# MIMXRT1064 register map
Vendor: nxp.com; File version: 1.0
CPU: CM7 r0p1, little endian, MPU, FPU, VTOR, 4 interrupt priority bits
Registers are 32-bit, read-write, reset 0x0 unless marked. A register's access mark holds for its fields unless they carry their own. Offsets are from the block's base; [hi:lo] are bit positions; lines under a group give offsets from that group; {n}, {i} and the like mark numbered series; 'fields as' and 'values as' point back to an identical list.

## DMA0 — DMA
Base 0x400E8000
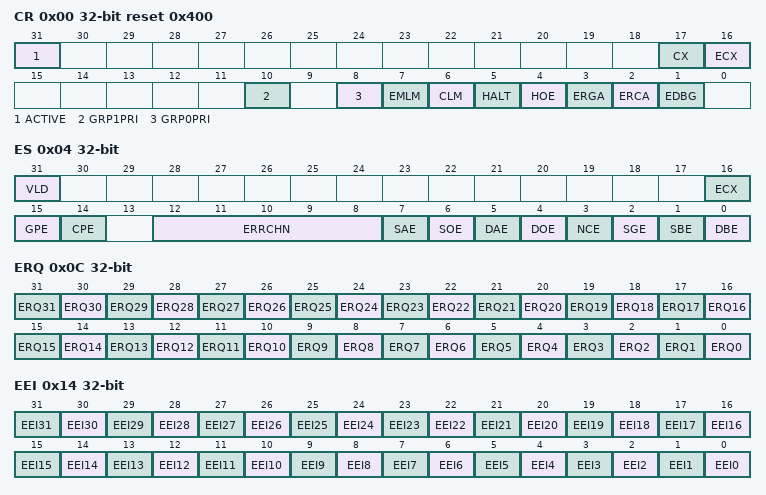
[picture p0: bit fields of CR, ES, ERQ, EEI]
0x00 CR reset 0x400 — Control Register
  [31] ACTIVE ro — DMA Active Status
    0=eDMA is idle; 1=eDMA is executing a channel
  [17] CX — Cancel Transfer
    0=Normal operation; 1=Cancel the remaining data transfer. Stop the executing channel and force the minor loop to finish. The cancel takes effect after the last write of the current read/write sequence. The CX bit clears itself after the cancel has been honored. This cancel retires the channel normally as if the minor loop was completed.
  [16] ECX — Error Cancel Transfer
    0=Normal operation; 1=Cancel the remaining data transfer in the same fashion as the CX bit. Stop the executing channel and force the minor loop to finish. The cancel takes effect after the last write of the current read/write sequence. The ECX bit clears itself after the cancel is honored. In addition to cancelling the transfer, ECX treats the cancel as an error condition, thus updating the Error Status register (DMAx_ES) and generating an optional error interrupt.
  [10] GRP1PRI — Channel Group 1 Priority
  [8] GRP0PRI — Channel Group 0 Priority
  [7] EMLM — Enable Minor Loop Mapping
    0=Disabled. TCDn.word2 is defined as a 32-bit NBYTES field.; 1=Enabled. TCDn.word2 is redefined to include individual enable fields, an offset field, and the NBYTES field. The individual enable fields allow the minor loop offset to be applied to the source address, the destination address, or both. The NBYTES field is reduced when either offset is enabled.
  [6] CLM — Continuous Link Mode
    0=A minor loop channel link made to itself goes through channel arbitration before being activated again; 1=A minor loop channel link made to itself does not go through channel arbitration before being activated again. Upon minor loop completion, the channel activates again if that channel has a minor loop channel link enabled and the link channel is itself. This effectively applies the minor loop offsets and restarts the next minor loop.
  [5] HALT — Halt DMA Operations
    0=Normal operation; 1=Stall the start of any new channels. Executing channels are allowed to complete. Channel execution resumes when this bit is cleared.
  [4] HOE — Halt On Error
    0=Normal operation; 1=Any error causes the HALT bit to set. Subsequently, all service requests are ignored until the HALT bit is cleared.
  [3] ERGA — Enable Round Robin Group Arbitration
    0=Fixed priority arbitration is used for selection among the groups; 1=Round robin arbitration is used for selection among the groups
  [2] ERCA — Enable Round Robin Channel Arbitration
    0=Fixed priority arbitration is used for channel selection within each group; 1=Round robin arbitration is used for channel selection within each group
  [1] EDBG — Enable Debug
    0=When in debug mode, the DMA continues to operate; 1=When in debug mode, the DMA stalls the start of a new channel. Executing channels are allowed to complete. Channel execution resumes when the system exits debug mode or the EDBG bit is cleared.
0x04 ES ro — Error Status Register
  [31] VLD
    0=No ERR bits are set; 1=At least one ERR bit is set indicating a valid error exists that has not been cleared
  [16] ECX — Transfer Canceled
    0=No canceled transfers; 1=The last recorded entry was a canceled transfer by the error cancel transfer input
  [15] GPE — Group Priority Error
    0=No group priority error; 1=The last recorded error was a configuration error among the group priorities. All group priorities are not unique.
  [14] CPE — Channel Priority Error
    0=No channel priority error; 1=The last recorded error was a configuration error in the channel priorities within a group. Channel priorities within a group are not unique.
  [12:8] ERRCHN — Error Channel Number or Canceled Channel Number
  [7] SAE — Source Address Error
    0=No source address configuration error; 1=The last recorded error was a configuration error detected in the TCDn_SADDR field. TCDn_SADDR is inconsistent with TCDn_ATTR[SSIZE].
  [6] SOE — Source Offset Error
    0=No source offset configuration error; 1=The last recorded error was a configuration error detected in the TCDn_SOFF field. TCDn_SOFF is inconsistent with TCDn_ATTR[SSIZE].
  [5] DAE — Destination Address Error
    0=No destination address configuration error; 1=The last recorded error was a configuration error detected in the TCDn_DADDR field. TCDn_DADDR is inconsistent with TCDn_ATTR[DSIZE].
  [4] DOE — Destination Offset Error
    0=No destination offset configuration error; 1=The last recorded error was a configuration error detected in the TCDn_DOFF field. TCDn_DOFF is inconsistent with TCDn_ATTR[DSIZE].
  [3] NCE — NBYTES/CITER Configuration Error
    0=No NBYTES/CITER configuration error; 1=The last recorded error was a configuration error detected in the TCDn_NBYTES or TCDn_CITER fields. TCDn_NBYTES is not a multiple of TCDn_ATTR[SSIZE] and TCDn_ATTR[DSIZE], or TCDn_CITER[CITER] is equal to zero, or TCDn_CITER[ELINK] is not equal to TCDn_BITER[ELINK]
  [2] SGE — Scatter/Gather Configuration Error
    0=No scatter/gather configuration error; 1=The last recorded error was a configuration error detected in the TCDn_DLASTSGA field. This field is checked at the beginning of a scatter/gather operation after major loop completion if TCDn_CSR[ESG] is enabled. TCDn_DLASTSGA is not on a 32 byte boundary.
  [1] SBE — Source Bus Error
    0=No source bus error; 1=The last recorded error was a bus error on a source read
  [0] DBE — Destination Bus Error
    0=No destination bus error; 1=The last recorded error was a bus error on a destination write
0x0C ERQ — Enable Request Register
  [all] fields
    0=The DMA request signal for the corresponding channel is disabled; 1=The DMA request signal for the corresponding channel is enabled
  [n] ERQ{n} (n=0..31) — Enable DMA Request {n}
0x14 EEI — Enable Error Interrupt Register
  [all] fields
    0=The error signal for corresponding channel does not generate an error interrupt; 1=The assertion of the error signal for corresponding channel generates an error interrupt request
  [n] EEI{n} (n=0..31) — Enable Error Interrupt {n}
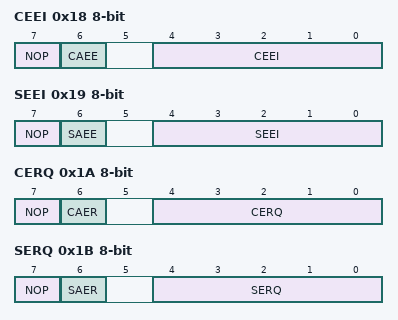
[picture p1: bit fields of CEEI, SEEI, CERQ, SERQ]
0x18 CEEI 8-bit — Clear Enable Error Interrupt Register
  [7] NOP — No Op enable
    0=Normal operation; 1=No operation, ignore the other bits in this register
  [6] CAEE — Clear All Enable Error Interrupts
    0=Clear only the EEI bit specified in the CEEI field; 1=Clear all bits in EEI
  [4:0] CEEI — Clear Enable Error Interrupt
0x19 SEEI 8-bit — Set Enable Error Interrupt Register
  [7] NOP — No Op enable
    values as CEEI.NOP
  [6] SAEE — Sets All Enable Error Interrupts
    0=Set only the EEI bit specified in the SEEI field; 1=Sets all bits in EEI
  [4:0] SEEI — Set Enable Error Interrupt
0x1A CERQ 8-bit — Clear Enable Request Register
  [7] NOP — No Op enable
    values as CEEI.NOP
  [6] CAER — Clear All Enable Requests
    0=Clear only the ERQ bit specified in the CERQ field; 1=Clear all bits in ERQ
  [4:0] CERQ — Clear Enable Request
0x1B SERQ 8-bit — Set Enable Request Register
  [7] NOP — No Op enable
    values as CEEI.NOP
  [6] SAER — Set All Enable Requests
    0=Set only the ERQ bit specified in the SERQ field; 1=Set all bits in ERQ
  [4:0] SERQ — Set Enable Request
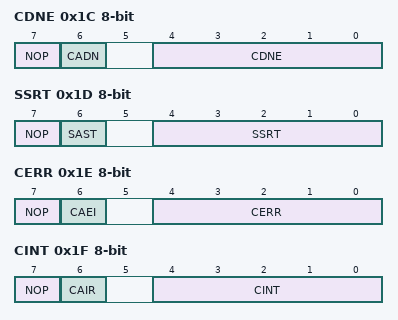
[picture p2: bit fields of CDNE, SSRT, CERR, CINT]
0x1C CDNE 8-bit — Clear DONE Status Bit Register
  [7] NOP — No Op enable
    values as CEEI.NOP
  [6] CADN — Clears All DONE Bits
    0=Clears only the TCDn_CSR[DONE] bit specified in the CDNE field; 1=Clears all bits in TCDn_CSR[DONE]
  [4:0] CDNE — Clear DONE Bit
0x1D SSRT 8-bit — Set START Bit Register
  [7] NOP — No Op enable
    values as CEEI.NOP
  [6] SAST — Set All START Bits (activates all channels)
    0=Set only the TCDn_CSR[START] bit specified in the SSRT field; 1=Set all bits in TCDn_CSR[START]
  [4:0] SSRT — Set START Bit
0x1E CERR 8-bit — Clear Error Register
  [7] NOP — No Op enable
    values as CEEI.NOP
  [6] CAEI — Clear All Error Indicators
    0=Clear only the ERR bit specified in the CERR field; 1=Clear all bits in ERR
  [4:0] CERR — Clear Error Indicator
0x1F CINT 8-bit — Clear Interrupt Request Register
  [7] NOP — No Op enable
    values as CEEI.NOP
  [6] CAIR — Clear All Interrupt Requests
    0=Clear only the INT bit specified in the CINT field; 1=Clear all bits in INT
  [4:0] CINT — Clear Interrupt Request
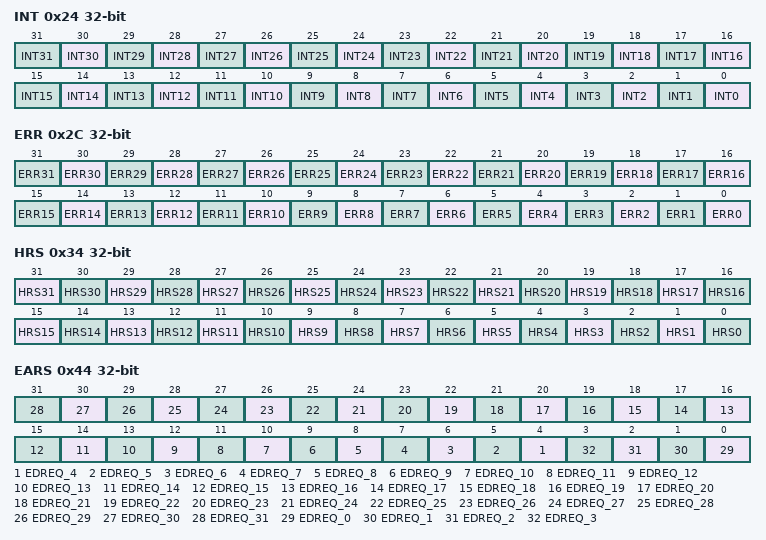
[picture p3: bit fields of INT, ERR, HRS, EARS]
0x24 INT — Interrupt Request Register
  [all] fields
    0=The interrupt request for corresponding channel is cleared; 1=The interrupt request for corresponding channel is active
  [n] INT{n} write-1-clears (n=0..31) — Interrupt Request {n}
0x2C ERR — Error Register
  [all] fields
    0=An error in this channel has not occurred; 1=An error in this channel has occurred
  [n] ERR{n} write-1-clears (n=0..31) — Error In Channel {n}
0x34 HRS ro — Hardware Request Status Register
  [31] HRS31 — Hardware Request Status Channel 31
    0=A hardware service request for channel 31 is not present; 1=A hardware service request for channel 31 is present
  [30] HRS30 — Hardware Request Status Channel 30
    0=A hardware service request for channel 30 is not present; 1=A hardware service request for channel 30 is present
  [29] HRS29 — Hardware Request Status Channel 29
    0=A hardware service request for channel 29 is not preset; 1=A hardware service request for channel 29 is present
  [n] HRS{n} (n=0..28) — Hardware Request Status Channel {n}
    0=A hardware service request for channel {n} is not present; 1=A hardware service request for channel {n} is present
0x44 EARS — Enable Asynchronous Request in Stop Register
  [n] EDREQ_{n} (n=4..31) — Enable asynchronous DMA request in stop mode for channel {n}
    0=Disable asynchronous DMA request for channel {n}; 1=Enable asynchronous DMA request for channel {n}
  [n] EDREQ_{n} (n=0..3) — Enable asynchronous DMA request in stop mode for channel {n}.
    values as EDREQ_4
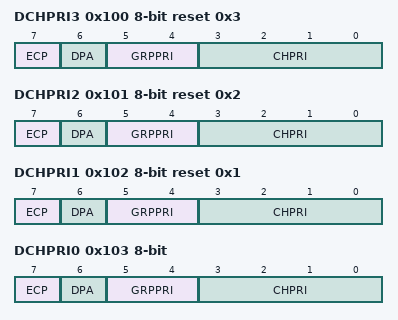
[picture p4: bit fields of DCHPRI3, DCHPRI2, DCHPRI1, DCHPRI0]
0x100 DCHPRI3 8-bit reset 0x3 — Channel n Priority Register
  [7] ECP — Enable Channel Preemption. This field resets to 0.
    0=Channel n cannot be suspended by a higher priority channel's service request; 1=Channel n can be temporarily suspended by the service request of a higher priority channel
  [6] DPA — Disable Preempt Ability. This field resets to 0.
    0=Channel n can suspend a lower priority channel; 1=Channel n cannot suspend any channel, regardless of channel priority
  [5:4] GRPPRI ro — Channel n Current Group Priority
  [3:0] CHPRI — Channel n Arbitration Priority
0x101 DCHPRI2 8-bit reset 0x2 — Channel n Priority Register
  fields as DCHPRI3
0x102 DCHPRI1 8-bit reset 0x1 — Channel n Priority Register
  fields as DCHPRI3
0x103 DCHPRI0 8-bit — Channel n Priority Register
  fields as DCHPRI3
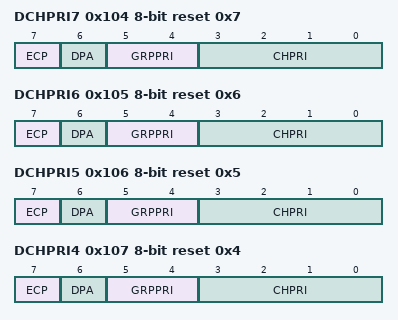
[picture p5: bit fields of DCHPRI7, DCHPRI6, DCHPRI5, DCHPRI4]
0x104 DCHPRI7 8-bit reset 0x7 — Channel n Priority Register
  fields as DCHPRI3
0x105 DCHPRI6 8-bit reset 0x6 — Channel n Priority Register
  fields as DCHPRI3
0x106 DCHPRI5 8-bit reset 0x5 — Channel n Priority Register
  fields as DCHPRI3
0x107 DCHPRI4 8-bit reset 0x4 — Channel n Priority Register
  fields as DCHPRI3
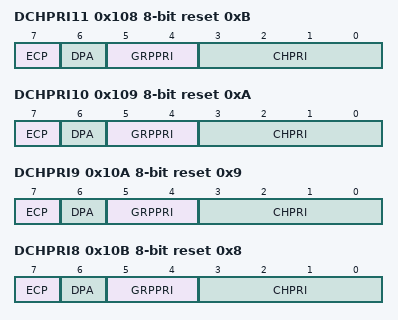
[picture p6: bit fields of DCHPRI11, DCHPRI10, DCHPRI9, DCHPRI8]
0x108 DCHPRI11 8-bit reset 0xB — Channel n Priority Register
  fields as DCHPRI3
0x109 DCHPRI10 8-bit reset 0xA — Channel n Priority Register
  fields as DCHPRI3
0x10A DCHPRI9 8-bit reset 0x9 — Channel n Priority Register
  fields as DCHPRI3
0x10B DCHPRI8 8-bit reset 0x8 — Channel n Priority Register
  fields as DCHPRI3
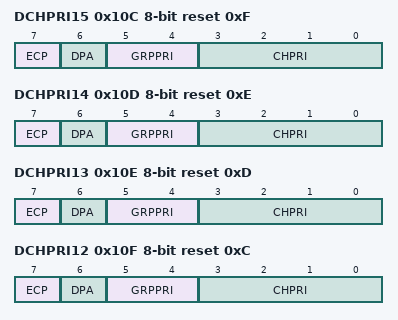
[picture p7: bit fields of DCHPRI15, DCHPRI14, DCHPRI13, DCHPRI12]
0x10C DCHPRI15 8-bit reset 0xF — Channel n Priority Register
  fields as DCHPRI3
0x10D DCHPRI14 8-bit reset 0xE — Channel n Priority Register
  fields as DCHPRI3
0x10E DCHPRI13 8-bit reset 0xD — Channel n Priority Register
  fields as DCHPRI3
0x10F DCHPRI12 8-bit reset 0xC — Channel n Priority Register
  fields as DCHPRI3
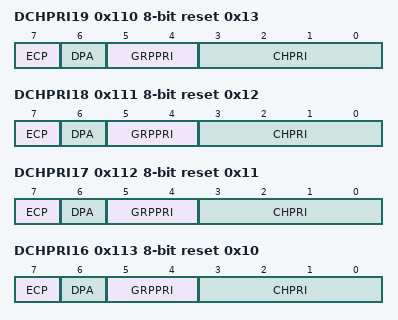
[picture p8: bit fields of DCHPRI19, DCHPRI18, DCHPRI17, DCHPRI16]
0x110 DCHPRI19 8-bit reset 0x13 — Channel n Priority Register
  fields as DCHPRI3
0x111 DCHPRI18 8-bit reset 0x12 — Channel n Priority Register
  fields as DCHPRI3
0x112 DCHPRI17 8-bit reset 0x11 — Channel n Priority Register
  fields as DCHPRI3
0x113 DCHPRI16 8-bit reset 0x10 — Channel n Priority Register
  fields as DCHPRI3
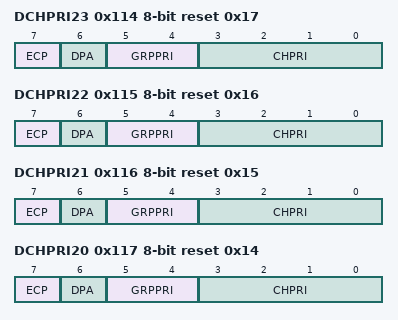
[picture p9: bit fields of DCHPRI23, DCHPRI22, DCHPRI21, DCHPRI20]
0x114 DCHPRI23 8-bit reset 0x17 — Channel n Priority Register
  fields as DCHPRI3
0x115 DCHPRI22 8-bit reset 0x16 — Channel n Priority Register
  fields as DCHPRI3
0x116 DCHPRI21 8-bit reset 0x15 — Channel n Priority Register
  fields as DCHPRI3
0x117 DCHPRI20 8-bit reset 0x14 — Channel n Priority Register
  fields as DCHPRI3
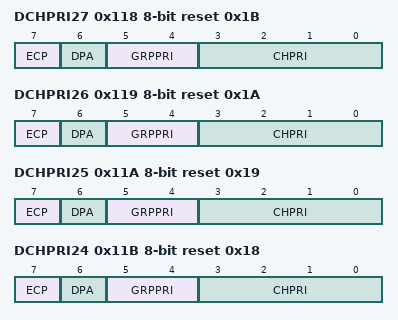
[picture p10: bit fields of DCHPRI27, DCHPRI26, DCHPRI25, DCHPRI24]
0x118 DCHPRI27 8-bit reset 0x1B — Channel n Priority Register
  fields as DCHPRI3
0x119 DCHPRI26 8-bit reset 0x1A — Channel n Priority Register
  fields as DCHPRI3
0x11A DCHPRI25 8-bit reset 0x19 — Channel n Priority Register
  fields as DCHPRI3
0x11B DCHPRI24 8-bit reset 0x18 — Channel n Priority Register
  fields as DCHPRI3
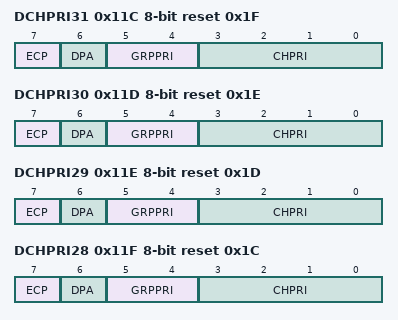
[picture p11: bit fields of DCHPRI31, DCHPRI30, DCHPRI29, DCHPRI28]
0x11C DCHPRI31 8-bit reset 0x1F — Channel n Priority Register
  fields as DCHPRI3
0x11D DCHPRI30 8-bit reset 0x1E — Channel n Priority Register
  fields as DCHPRI3
0x11E DCHPRI29 8-bit reset 0x1D — Channel n Priority Register
  fields as DCHPRI3
0x11F DCHPRI28 8-bit reset 0x1C — Channel n Priority Register
  fields as DCHPRI3
{0x1000+0x20*i} TCD{i}_SADDR reset not defined (i=0..31) — TCD Source Address
  [31:0] SADDR — Source Address
{0x1004+0x20*i} TCD{i}_SOFF 16-bit reset not defined (i=0..31) — TCD Signed Source Address Offset
  [15:0] SOFF — Source address signed offset
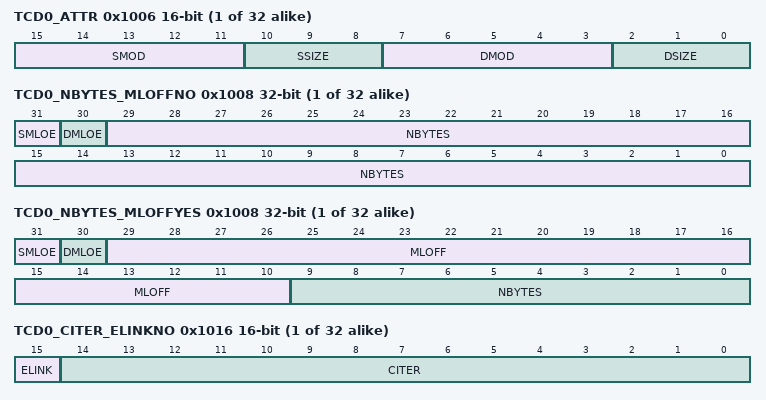
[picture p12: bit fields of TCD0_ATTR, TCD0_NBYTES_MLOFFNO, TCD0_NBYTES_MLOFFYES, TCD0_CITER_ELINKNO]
{0x1006+0x20*i} TCD{i}_ATTR 16-bit reset not defined (i=0..31) — TCD Transfer Attributes
  [15:11] SMOD — Source Address Modulo
    0=Source address modulo feature is disabled; {v}=This value defines a specific address range specified to be the value after SADDR + SOFF calculation is performed on the original register value. Setting this field provides the ability to implement a circular data queue easily. For data queues requiring power-of-2 size bytes, the queue should start at a 0-modulo-size address and the SMOD field should be set to the appropriate value for the queue, freezing the desired number of upper address bits. The value programmed into this field specifies the number of lower address bits allowed to change. For a circular queue application, the SOFF is typically set to the transfer size to implement post-increment addressing with the SMOD function constraining the addresses to a 0-modulo-size range. (v=1..9)
  [10:8] SSIZE — Source data transfer size
    0=8-bit; 1=16-bit; 2=32-bit; 3=64-bit; 5=32-byte burst (4 beats of 64 bits)
  [7:3] DMOD — Destination Address Modulo
  [2:0] DSIZE — Destination data transfer size
{0x1008+0x20*i} TCD{i}_NBYTES_MLNO reset not defined (TCD_NBYTES view) (i=0..31) — TCD Minor Byte Count (Minor Loop Mapping Disabled)
  [31:0] NBYTES — Minor Byte Transfer Count
{0x1008+0x20*i} TCD{i}_NBYTES_MLOFFNO reset not defined (TCD_NBYTES view) (i=0..31) — TCD Signed Minor Loop Offset (Minor Loop Mapping Enabled and Offset Disabled)
  [31] SMLOE — Source Minor Loop Offset Enable
    0=The minor loop offset is not applied to the SADDR; 1=The minor loop offset is applied to the SADDR
  [30] DMLOE — Destination Minor Loop Offset enable
    0=The minor loop offset is not applied to the DADDR; 1=The minor loop offset is applied to the DADDR
  [29:0] NBYTES — Minor Byte Transfer Count
{0x1008+0x20*i} TCD{i}_NBYTES_MLOFFYES reset not defined (TCD_NBYTES view) (i=0..31) — TCD Signed Minor Loop Offset (Minor Loop Mapping and Offset Enabled)
  [31] SMLOE — Source Minor Loop Offset Enable
    values as TCD0_NBYTES_MLOFFNO.SMLOE
  [30] DMLOE — Destination Minor Loop Offset enable
    values as TCD0_NBYTES_MLOFFNO.DMLOE
  [29:10] MLOFF — If SMLOE or DMLOE is set, this field represents a sign-extended offset applied to the source or destination address to form the next-state value after the minor loop completes.
  [9:0] NBYTES — Minor Byte Transfer Count
{0x100C+0x20*i} TCD{i}_SLAST reset not defined (i=0..31) — TCD Last Source Address Adjustment
  [31:0] SLAST — Last Source Address Adjustment
{0x1010+0x20*i} TCD{i}_DADDR reset not defined (i=0..31) — TCD Destination Address
  [31:0] DADDR — Destination Address
{0x1014+0x20*i} TCD{i}_DOFF 16-bit reset not defined (i=0..31) — TCD Signed Destination Address Offset
  [15:0] DOFF — Destination Address Signed Offset
{0x1016+0x20*i} TCD{i}_CITER_ELINKNO 16-bit reset not defined (TCD_CITER_ELINK view) (i=0..31) — TCD Current Minor Loop Link, Major Loop Count (Channel Linking Disabled)
  [15] ELINK — Enable channel-to-channel linking on minor-loop complete
    0=The channel-to-channel linking is disabled; 1=The channel-to-channel linking is enabled
  [14:0] CITER — Current Major Iteration Count
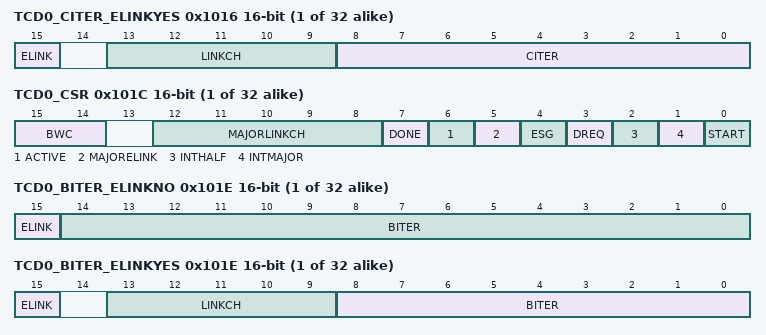
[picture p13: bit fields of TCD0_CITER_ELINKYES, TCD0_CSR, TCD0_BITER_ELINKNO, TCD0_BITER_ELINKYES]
{0x1016+0x20*i} TCD{i}_CITER_ELINKYES 16-bit reset not defined (TCD_CITER_ELINK view) (i=0..31) — TCD Current Minor Loop Link, Major Loop Count (Channel Linking Enabled)
  [15] ELINK — Enable channel-to-channel linking on minor-loop complete
    values as TCD0_CITER_ELINKNO.ELINK
  [13:9] LINKCH — Minor Loop Link Channel Number
  [8:0] CITER — Current Major Iteration Count
{0x1018+0x20*i} TCD{i}_DLASTSGA reset not defined (i=0..31) — TCD Last Destination Address Adjustment/Scatter Gather Address
{0x101C+0x20*i} TCD{i}_CSR 16-bit reset not defined (i=0..31) — TCD Control and Status
  [15:14] BWC — Bandwidth Control
    0=No eDMA engine stalls; 2=eDMA engine stalls for 4 cycles after each R/W; 3=eDMA engine stalls for 8 cycles after each R/W
  [12:8] MAJORLINKCH — Major Loop Link Channel Number
  [7] DONE write-0-clears — Channel Done
  [6] ACTIVE ro — Channel Active
  [5] MAJORELINK — Enable channel-to-channel linking on major loop complete
    values as TCD0_CITER_ELINKNO.ELINK
  [4] ESG — Enable Scatter/Gather Processing
    0=The current channel's TCD is normal format; 1=The current channel's TCD specifies a scatter gather format. The DLASTSGA field provides a memory pointer to the next TCD to be loaded into this channel after the major loop completes its execution.
  [3] DREQ — Disable Request
    0=The channel's ERQ bit is not affected; 1=The channel's ERQ bit is cleared when the major loop is complete
  [2] INTHALF — Enable an interrupt when major counter is half complete.
    0=The half-point interrupt is disabled; 1=The half-point interrupt is enabled
  [1] INTMAJOR — Enable an interrupt when major iteration count completes.
    0=The end-of-major loop interrupt is disabled; 1=The end-of-major loop interrupt is enabled
  [0] START — Channel Start
    0=The channel is not explicitly started; 1=The channel is explicitly started via a software initiated service request
{0x101E+0x20*i} TCD{i}_BITER_ELINKNO 16-bit reset not defined (TCD_BITER_ELINK view) (i=0..31) — TCD Beginning Minor Loop Link, Major Loop Count (Channel Linking Disabled)
  [15] ELINK — Enables channel-to-channel linking on minor loop complete
    values as TCD0_CITER_ELINKNO.ELINK
  [14:0] BITER — Starting Major Iteration Count
{0x101E+0x20*i} TCD{i}_BITER_ELINKYES 16-bit reset not defined (TCD_BITER_ELINK view) (i=0..31) — TCD Beginning Minor Loop Link, Major Loop Count (Channel Linking Enabled)
  [15] ELINK — Enables channel-to-channel linking on minor loop complete
    values as TCD0_CITER_ELINKNO.ELINK
  [13:9] LINKCH — Link Channel Number
  [8:0] BITER — Starting major iteration count
